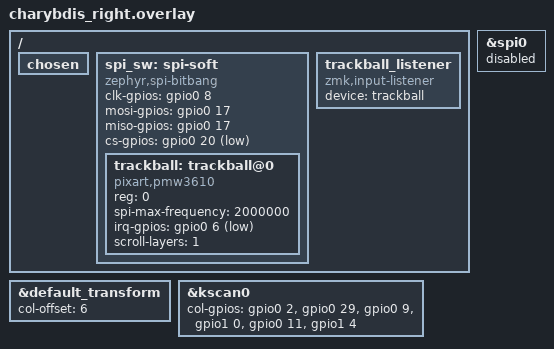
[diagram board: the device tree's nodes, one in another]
/*
 * Copyright (c) 2020 ZMK Contributors
 *
 * SPDX-License-Identifier: MIT
 */

#include "charybdis.dtsi"

&default_transform {
    col-offset = <6>;
};

// [1] 배터리 노드 관련 에러 방지 및 n키(P0.29) 해방
/ {
    chosen {
        /delete-property/ zmk,battery;
    };

    /delete-node/ vbatt;
};

// [2] 오른쪽 버튼 핀 설정 (29번 포함)
&kscan0 {
    col-gpios
        = <&gpio0 2  (GPIO_ACTIVE_HIGH | GPIO_PULL_DOWN)>
        , <&gpio0 29 (GPIO_ACTIVE_HIGH | GPIO_PULL_DOWN)>
        , <&gpio0 9  (GPIO_ACTIVE_HIGH | GPIO_PULL_DOWN)>
        , <&gpio1 0  (GPIO_ACTIVE_HIGH | GPIO_PULL_DOWN)>
        , <&gpio0 11 (GPIO_ACTIVE_HIGH | GPIO_PULL_DOWN)>
        , <&gpio1 4  (GPIO_ACTIVE_HIGH | GPIO_PULL_DOWN)>
        ;
};

// [3] 하드웨어 SPI는 끄고 (에러의 원인)
&spi0 {
    status = "disabled";
};

// [4] 소프트웨어 SPI로 트랙볼 연결 (pinctrl 에러 없음)
/ {
    spi_sw: spi-soft {
        compatible = "zephyr,spi-bitbang";
        #address-cells = <1>;
        #size-cells = <0>;
        clk-gpios  = <&gpio0 8  GPIO_ACTIVE_HIGH>;   // SCK
        mosi-gpios = <&gpio0 17 GPIO_ACTIVE_HIGH>;  // MOSI
        miso-gpios = <&gpio0 17 GPIO_ACTIVE_HIGH>;  // MISO (공유)
        cs-gpios   = <&gpio0 20 GPIO_ACTIVE_LOW>;   // CS

        trackball: trackball@0 {
            compatible = "pixart,pmw3610";
            reg = <0>;
            spi-max-frequency = <2000000>;
            irq-gpios = <&gpio0 6 (GPIO_ACTIVE_LOW | GPIO_PULL_UP)>;
            scroll-layers = <1>;
        };
    };

    trackball_listener {
        compatible = "zmk,input-listener";
        device = <&trackball>;
    };
};
